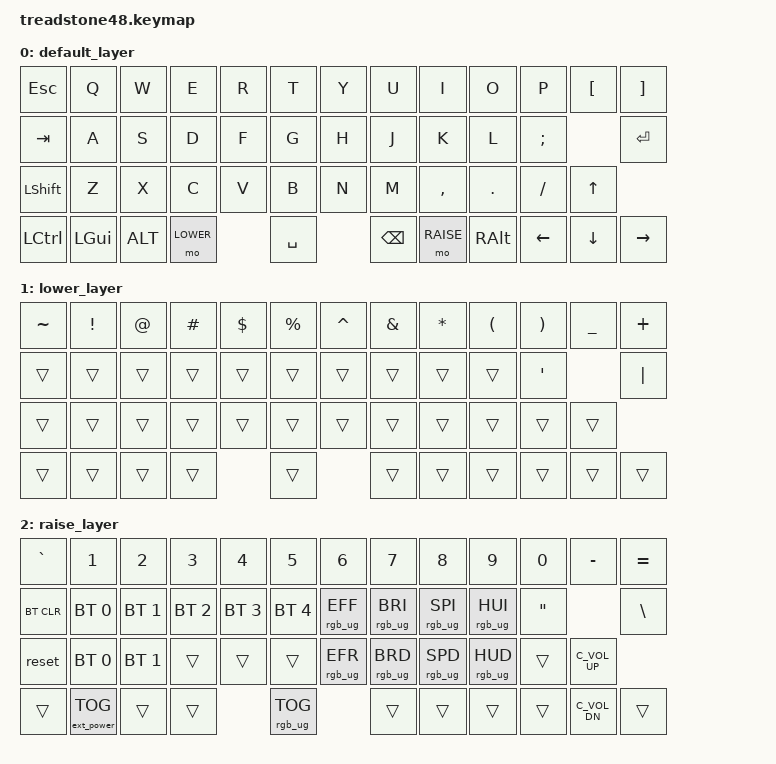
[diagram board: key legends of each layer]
/*
 * Copyright (c) 2021 The ZMK Contributors
 *
 * SPDX-License-Identifier: MIT
 */

#include <behaviors.dtsi>
#include <dt-bindings/zmk/keys.h>
#include <dt-bindings/zmk/bt.h>
#include <dt-bindings/zmk/rgb.h>
#include <dt-bindings/zmk/outputs.h>

#define DEFAULT 0
#define LOWER   1
#define RAISE   2
#define BT_0 BT_SEL 0
#define BT_1 BT_SEL 1

/ {
        keymap {
                compatible = "zmk,keymap";

                default_layer {
// -----------------------------------------------------------------------------------------
//     | ESC |  Q  |  W  |  E  |  R  |  T  |   |  Y  |  U   |  I  |  O  |  P  |  [  |  ]  |
//     |  TAB |  A  |  S  |  D  |  F  |  G  | |  H  |  J   |  K  |  L  |  ;  |    ENT     |
// | LSHIFT  |  Z  |  X  |  C  |  V  |  B  |   |  N  |  M   |  ,  |  .  |  /  | UP  | 
//    | CTL | GUI  |  ALT  |  LWR | |  SPC  | |    BKSP    | RSE  | ALT | LFT | DWN | RGT |
                        bindings = <
    &kp ESC    &kp Q         &kp W        &kp E       &kp R        &kp T          &kp Y    &kp U    &kp I     &kp O    &kp P    &kp LBKT &kp RBKT
    &kp TAB    &kp A         &kp S        &kp D       &kp F        &kp G          &kp H    &kp J    &kp K     &kp L    &kp SEMI          &kp ENTER
    &kp LSHFT  &kp Z         &kp X        &kp C       &kp V        &kp B          &kp N    &kp M    &kp COMMA &kp DOT  &kp FSLH &kp UP
    &kp LCTRL  &kp LGUI      &kp ALT      &mo LOWER                &kp SPACE               &kp BSPC &mo RAISE &kp RALT &kp LEFT &kp DOWN &kp RIGHT
                        >;
                };

                lower_layer {
// -----------------------------------------------------------------------------------------
// |   ~  |  !  |  @  |  #  |  $  |  %  |   |  ^  |  &  |  *  |  (  |  )  |  _  |  +  |
// |      |     |     |     |     |     |   |     |     |     |     | SQT |    "|"    |
// |      |     |     |     |     |     |   |     |     |     |     |     |     |
//            
                        bindings = <
    &kp TILDE  &kp EXCL     &kp AT       &kp HASH     &kp DLLR     &kp PRCNT      &kp CARET &kp AMPS &kp STAR &kp LPAR &kp RPAR &kp UNDER &kp PLUS
    &trans     &trans       &trans       &trans       &trans       &trans         &trans    &trans   &trans   &trans   &kp SQT            &kp PIPE
    &trans     &trans       &trans       &trans       &trans       &trans         &trans    &trans   &trans   &trans   &trans   &trans
    &trans     &trans       &trans       &trans                    &trans                   &trans   &trans   &trans   &trans   &trans    &trans
                        >;
                };

                raise_layer {
// -----------------------------------------------------------------------------------------
// |   `  |  1  |  2  |  3  |  4  |  5  |   |  6  |  7  |  8  |  9  |  0  |  -  |  =  |
// | BTCLR| BT1 | BT2 | BT3 | BT4 | BT5 |   |     |     |     |     |  '  |     \     |
// | SHFT |     |     |     |     |     |   |     |     |     |     |     |      |
//                    
                        bindings = <
    &kp GRAVE  &kp N1       &kp N2       &kp N3       &kp N4       &kp N5         &kp N6          &kp N7          &kp N8          &kp N9          &kp N0   &kp MINUS &kp EQUAL
    &bt BT_CLR &bt BT_SEL 0 &bt BT_SEL 1 &bt BT_SEL 2 &bt BT_SEL 3 &bt BT_SEL 4   &rgb_ug RGB_EFF &rgb_ug RGB_BRI &rgb_ug RGB_SPI &rgb_ug RGB_HUI &kp DQT            &kp BSLH
    &reset     &bt BT_0     &bt BT_1     &trans       &trans       &trans         &rgb_ug RGB_EFR &rgb_ug RGB_BRD &rgb_ug RGB_SPD &rgb_ug RGB_HUD &trans   C_VOL_UP
    &trans &ext_power EP_TOG &trans      &trans                    &rgb_ug RGB_TOG                &trans          &trans          &trans          &trans   C_VOL_DN  &trans
                        >;
                };

        };
};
